# MKE15Z7 register map
Vendor: Freescale Semiconductor, Inc.; Series: Kinetis_E; File version: 1.6
CPU: CM0PLUS r0p0, little endian, no MPU, no FPU, VTOR, 2 interrupt priority bits
Registers are 32-bit, read-write, reset 0x0 unless marked. A register's access mark holds for its fields unless they carry their own. Offsets are from the block's base; [hi:lo] are bit positions; {n}, {i} and the like mark numbered series.

## TSI — Touch sense input
Base 0x40045000; register names take the prefix TSI_
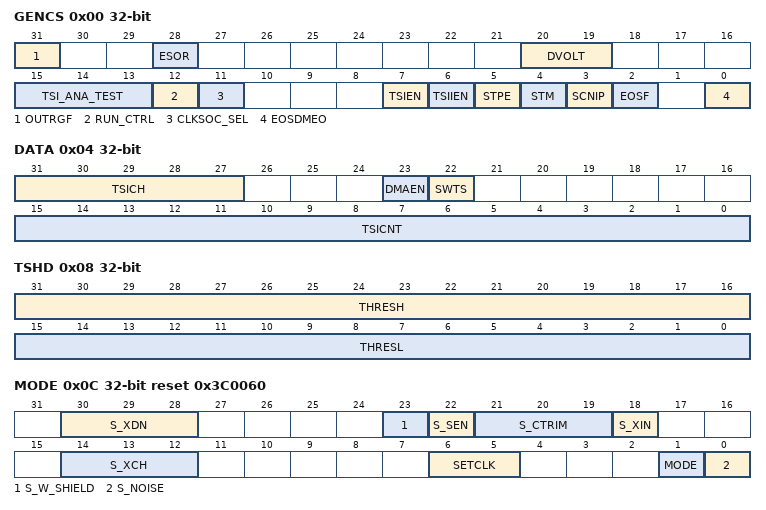
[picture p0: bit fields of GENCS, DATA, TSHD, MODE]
0x00 GENCS — TSI General Control and Status Register
  [31] OUTRGF — Out of Range Flag.
  [28] ESOR — End-of-scan or Out-of-Range Interrupt Selection
    0=Out-of-range interrupt is allowed; 1=End-of-scan interrupt is allowed
  [20:19] DVOLT
    0=Vm=0.3V; Vp=1.3V; dvolt=1.0V; 1=Vm=0.3V; Vp=1.6V; dvolt=1.3V; 2=Vm=0.3V; Vp=1.9V; dvolt=1.6V; 3=Vm=0.3V; Vp=2.3V; dvolt=2.0V
  [15:13] TSI_ANA_TEST
  [12] RUN_CTRL
  [11] CLKSOC_SEL
  [7] TSIEN — Touch Sensing Input Module Enable
    0=TSI module disabled; 1=TSI module enabled
  [6] TSIIEN — Touch Sensing Input Interrupt Enable
    0=TSI interrupt is disabled; 1=TSI interrupt is enabled
  [5] STPE — TSI STOP Enable
    0=TSI is disabled when MCU goes into low power mode; 1=Allows TSI to continue running in all low power modes
  [4] STM — Scan Trigger Mode
    0=Software trigger scan; 1=Hardware trigger scan
  [3] SCNIP ro — Scan In Progress Status
    0=No scan in progress; 1=Scan in progress
  [2] EOSF — End of Scan Flag
    0=Scan not complete; 1=Scan complete
  [0] EOSDMEO — End-of-Scan DMA Transfer Request Enable Only
    0=Do not enable the End-of-Scan DMA transfer request only. Depending on ESOR state, either Out-of-Range or End-of-Scan can trigger a DMA transfer request and interrupt.; 1=Only the End-of-Scan event can trigger a DMA transfer request. The Out-of-Range event only and always triggers an interrupt if TSIIE is set.
0x04 DATA — TSI DATA Register
  [31:27] TSICH
    {v}=For self-cap mode: Channel {v} (v=0..24)
  [23] DMAEN — DMA Transfer Enabled
    0=Interrupt is selected when the interrupt enable bit is set and the corresponding TSI events assert; 1=DMA transfer request is selected when the interrupt enable bit is set and the corresponding TSI events assert
  [22] SWTS wo — Software Trigger Start
    0=No effect; 1=Start a scan to determine which channel is specified by TSI_DATA[TSICH]
  [15:0] TSICNT ro — TSI Conversion Counter Value
0x08 TSHD — TSI Threshold Register
  [31:16] THRESH — TSI Wakeup Channel High-threshold
  [15:0] THRESL — TSI Wakeup Channel Low-threshold
0x0C MODE reset 0x3C0060 — TSI MODE Register
  [30:28] S_XDN
    0=1/16; 1=1/8; 2=1/4; 3=1/2; {v}=NA (v=4..7)
  [23] S_W_SHIELD
    0=shield switch off; 1=shield switch on
  [22] S_SEN
    0=Sensitivity boost off; 1=Sensitivity boost on
  [21:19] S_CTRIM — Capacitor trim setting
    0=Ctrim=2.5p; 1=Ctrim=5.0p; 2=Ctrim=7.5p; 3=Ctrim=10p; 4=Ctrim=12.5p; 5=Ctrim=15p; 6=Ctrim=17.5p; 7=Ctrim=20p
  [18] S_XIN
    0=1/8; 1=1/4
  [14:12] S_XCH
    0=1/16; 1=1/8; 2=1/4; 3=1/2; {v}=NA (v=4..7)
  [6:5] SETCLK
    0=20.72MHz; 1=16.65MHz; 2=13.87MHz; 3=11.91MHz
  [1] MODE
    0=self-cap mode; 1=mutual-cap mode
  [0] S_NOISE
    0=noise cancellation off; 1=noise cancellation on
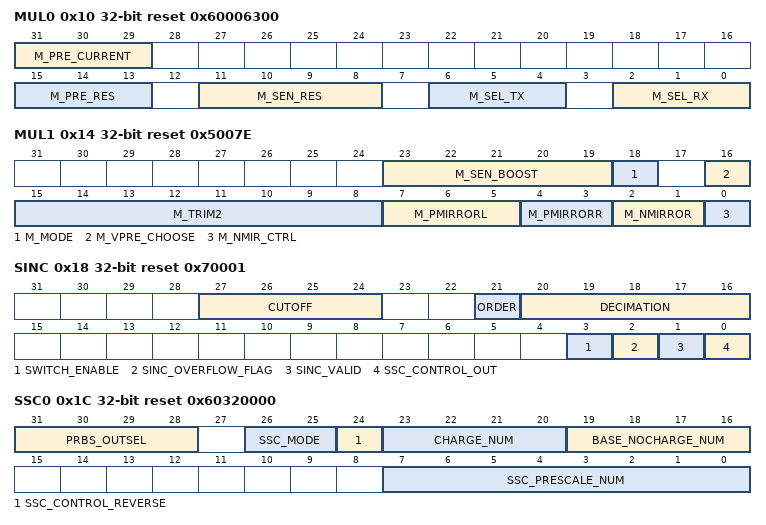
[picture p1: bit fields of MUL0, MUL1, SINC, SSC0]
0x10 MUL0 reset 0x60006300 — TSI MUTUAL-CAP Register 0
  [31:29] M_PRE_CURRENT
    {v}={v+1}uA (v=0..7)
  [15:13] M_PRE_RES
    {v}={v+1}k (v=0..7)
  [11:8] M_SEN_RES
    0=2.5k; 1=5k; 2=7.5k; 3=10k; 4=12.5k; 5=15k; 6=17.5k; 7=20k; 8=22.5k; 9=25k; 10=27.5k; 11=30k; 12=32.5k; 13=35k; 14=37.5k; 15=40k
  [6:4] M_SEL_TX
    {v}=select channel {v} as tx{v} (v=0..5); 6=NA; 7=NA
  [2:0] M_SEL_RX
    {v}=select channel {v+6} as rx{v+6} (v=0..5); 6=NA; 7=NA
0x14 MUL1 reset 0x5007E — TSI MUTUAL-CAP Register 1
  [23:19] M_SEN_BOOST
    0=0u; 1=2u; 2=4u; 3=6u; 4=8u; 5=10u; 6=12u; 7=14u; 8=16u; 9=18u; 10=20u; 11=22u; 12=24u; 13=26u; 14=28u; 15=30u; 16=32u; 17=34u; 18=36u; 19=38u; 20=40u; 21=42u; 22=44u; 23=46u; 24=48u; 25=50u; 26=52u; 27=54u; 28=56u; 29=58u; 30=60u; 31=62u
  [18] M_MODE
    0=-5V~+5V; 1=0V~+5V
  [16] M_VPRE_CHOOSE
    0=Internal 1.2V voltage; 1=1.2V PMC output
  [15:8] M_TRIM2
  [7:5] M_PMIRRORL
    0=m=4; 1=m=8; 2=m=12; 3=m=16; 4=m=20; 5=m=24; 6=m=28; 7=m=32
  [4:3] M_PMIRRORR
    {v}=m={v+1} (v=0..3)
  [2:1] M_NMIRROR
    {v}=m={v+1} (v=0..3)
  [0] M_NMIR_CTRL
    0=Enable NMOS mirror; 1=Disable NMOS mirror
0x18 SINC reset 0x70001 — TSI SINC filter Register
  [27:24] CUTOFF
    0=div=1; 1=div=2; 2=div=4; 3=div=8; 4=div=16; 5=div=32; 6=div=64; 7=div=128; {v}=NC (v=8..15)
  [21] ORDER
    0=Using 1 order SINC filter; 1=Using 2 order SINC filter
  [20:16] DECIMATION
    0=The TSI_DATA[TSICNT] bits is the counter value of 1 scan period; {v}=The TSI_DATA[TSICNT] bits is the counter value of {v+1} scan periods (v=1..31)
  [3] SWITCH_ENABLE ro
    0=SSC function is disabled; 1=SSC function is enabled
  [2] SINC_OVERFLOW_FLAG ro
    0=The counter result has no overflow occurrence in the last scan process; 1=The counter result has an overflow occurrence in the last scan process
  [1] SINC_VALID ro
    0=SINC filter is disabled; 1=SINC filter is enabled
  [0] SSC_CONTROL_OUT ro
    0=SSC output value is 0; 1=SSC output value is 1
0x1C SSC0 reset 0x60320000 — TSI SSC Register 0
  [31:28] PRBS_OUTSEL
    0=NC; 1=NC; {v}=The length of the PRBS is {v} (v=2..15)
  [26:25] SSC_MODE
    0=Using PRBS method generating SSC output bit; 1=Using up-down counter generating SSC output bit; 2=SSC function is disabled; 3=NC
  [24] SSC_CONTROL_REVERSE
    0=Keep the polarity of the SSC output bit; 1=Reverse the polarity of the SSC output bit
  [23:20] CHARGE_NUM
    0=The SSC output bit 0's period will be 1 clock cycle of system clock; {v}=The SSC output bit 0's period will be {v+1} clock cycles of system clock (v=1..15)
  [19:16] BASE_NOCHARGE_NUM
    0=The SSC output bit 1's basic period will be 1 clock cycle of system clock; {v}=The SSC output bit 1's basic period will be {v+1} clock cycles of system clock (v=1..15)
  [7:0] SSC_PRESCALE_NUM
    0=div2(2^0*2); 1=div4(2^1*2); 3=div8(2^2*2); 7=div16(2^3*2); 15=div32(2^4*2); 31=div64(2^5*2); 63=div128(2^6*2); 127=div256(2^7*2); 255=div512(2^8*2)
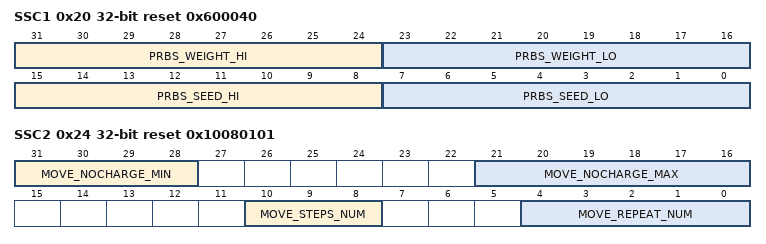
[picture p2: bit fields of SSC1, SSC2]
0x20 SSC1 reset 0x600040 — TSI SSC Register 0
  [31:24] PRBS_WEIGHT_HI, [23:16] PRBS_WEIGHT_LO, [15:8] PRBS_SEED_HI, [7:0] PRBS_SEED_LO
0x24 SSC2 reset 0x10080101 — TSI SSC Register 2
  [31:28] MOVE_NOCHARGE_MIN
    0=The SSC output bit 1's min period will be (1 + TSI_SSC0[BASE_ NOCHARGE_NUM]) clock cycle of system clock; {v}=The SSC output bit 1's min period will be ({v+1} + TSI_SSC0[BASE_ NOCHARGE_NUM]) clock cycles of system clock (v=1..15)
  [21:16] MOVE_NOCHARGE_MAX
  [10:8] MOVE_STEPS_NUM
    {v}=The added value for up-down counter is {v} (v=0..7)
  [4:0] MOVE_REPEAT_NUM
    0=The up_down counter will be updated for every sample-charge cycle; {v}=The up_down counter will be updated for every {v+1} sample-charge cycles (v=1..6)
